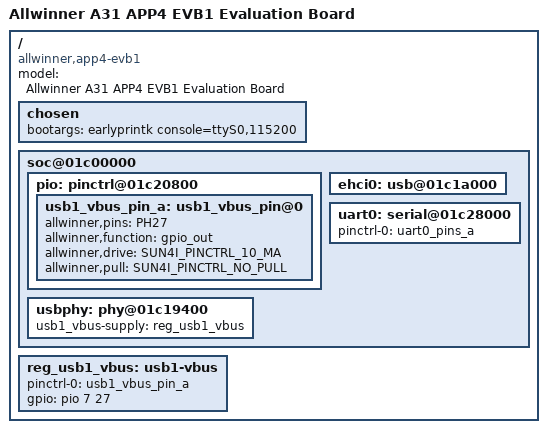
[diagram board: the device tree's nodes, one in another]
/*
 * Copyright 2014 Boris Brezillon
 *
 * Boris Brezillon <boris.brezillon@free-electrons.com>
 *
 * The code contained herein is licensed under the GNU General Public
 * License. You may obtain a copy of the GNU General Public License
 * Version 2 or later at the following locations:
 *
 * http://www.opensource.org/licenses/gpl-license.html
 * http://www.gnu.org/copyleft/gpl.html
 */

/dts-v1/;
#include "sun6i-a31.dtsi"
#include "sunxi-common-regulators.dtsi"

#include <dt-bindings/gpio/gpio.h>
#include <dt-bindings/pinctrl/sun4i-a10.h>

/ {
	model = "Allwinner A31 APP4 EVB1 Evaluation Board";
	compatible = "allwinner,app4-evb1", "allwinner,sun6i-a31";

	chosen {
		bootargs = "earlyprintk console=ttyS0,115200";
	};

	soc@01c00000 {
		pio: pinctrl@01c20800 {
			usb1_vbus_pin_a: usb1_vbus_pin@0 {
				allwinner,pins = "PH27";
				allwinner,function = "gpio_out";
				allwinner,drive = <SUN4I_PINCTRL_10_MA>;
				allwinner,pull = <SUN4I_PINCTRL_NO_PULL>;
			};
		};

		usbphy: phy@01c19400 {
			usb1_vbus-supply = <&reg_usb1_vbus>;
			status = "okay";
		};

		ehci0: usb@01c1a000 {
			status = "okay";
		};

		uart0: serial@01c28000 {
			pinctrl-names = "default";
			pinctrl-0 = <&uart0_pins_a>;
			status = "okay";
		};
	};

	reg_usb1_vbus: usb1-vbus {
		pinctrl-0 = <&usb1_vbus_pin_a>;
		gpio = <&pio 7 27 GPIO_ACTIVE_HIGH>;
		status = "okay";
	};
};
